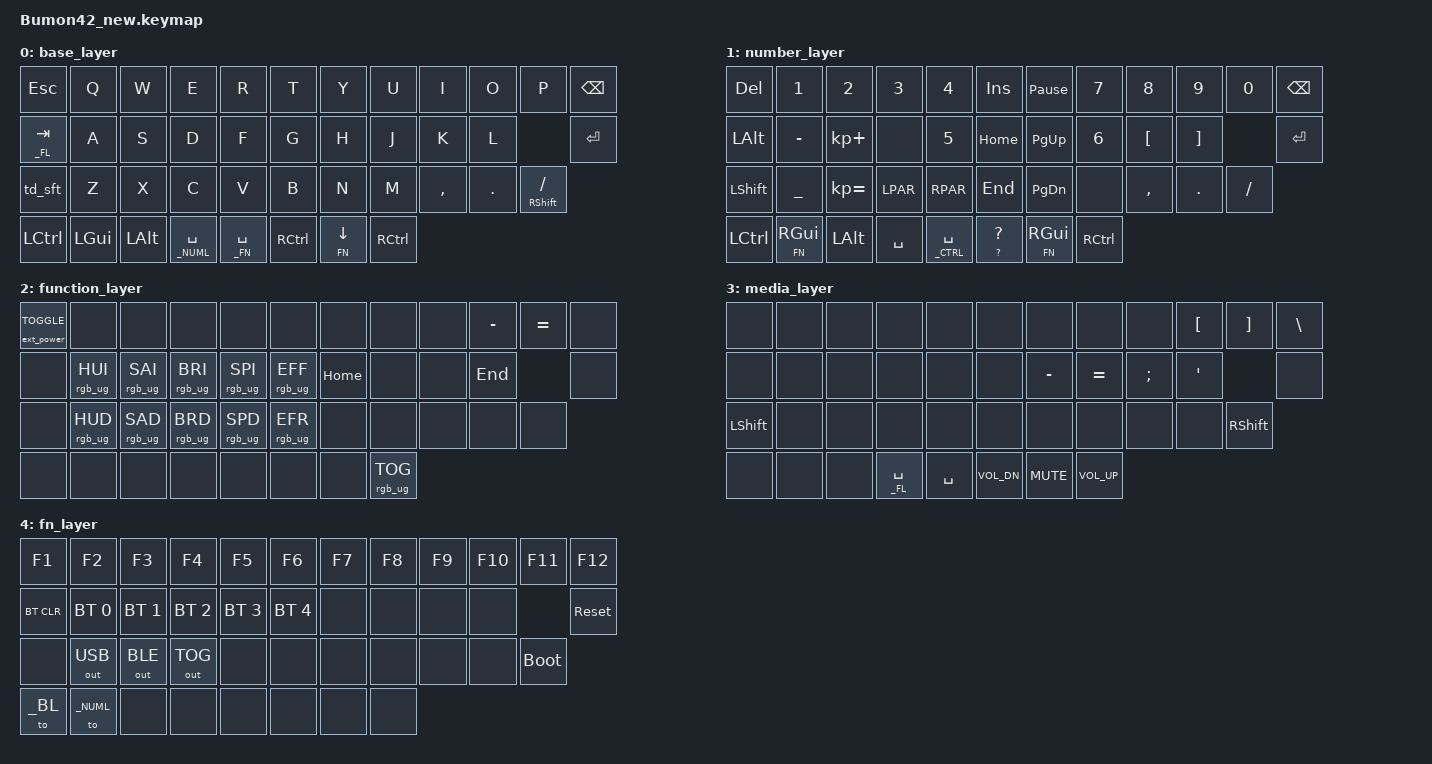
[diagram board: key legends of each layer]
#include <behaviors.dtsi>
#include <dt-bindings/zmk/bt.h>
#include <dt-bindings/zmk/ext_power.h>
#include <dt-bindings/zmk/keys.h>
#include <dt-bindings/zmk/outputs.h>
#include <dt-bindings/zmk/rgb.h>

// changed lwr and rse

#define _BL 0
#define _NUML 1
#define _FN 2
#define _CTRL 3
#define _FL 4
#define FN  5

/ {
    behaviors {
        td_sft: tap_dance_mod_tap {
            compatible = "zmk,behavior-tap-dance";
            label = "TAP_DANCE_0";
            #binding-cells = <0>;
            tapping-term-ms = <200>;
            bindings = <&kp LSHIFT>, <&kp CAPSLOCK>, <&kp TAB>;
        };
        // td_lt: tap_dance_mod_tap {
        //     compatible = "zmk,behavior-tap-dance";
        //     label = "TAP_DANCE_0";
        //     #binding-cells = <0>;
        //     tapping-term-ms = <200>;
        //     bindings = <&kp LSHIFT>, <&kp CAPSLOCK>, <&kp TAB>;
        // };
    };

    keymap {
        compatible = "zmk,keymap";

        base_layer {
            bindings = <
                &kp ESC   &kp Q    &kp W    &kp E         &kp R         &kp T     &kp Y       &kp U &kp I     &kp O   &kp P &kp BSPC
                &lt _FL TAB   &kp A    &kp S    &kp D         &kp F         &kp G     &kp H       &kp J &kp K     &kp L   &kp ENTER
                &td_sft &kp Z    &kp X    &kp C         &kp V         &kp B     &kp N       &kp M &kp COMMA &kp DOT &mt RSHIFT SLASH
                &kp LCTRL &kp LGUI &kp LALT &lt _NUML SPACE &lt _FN SPACE &kp RCTRL &lt FN DOWN &kp RCTRL
            >;

            // sensor-bindings = <&inc_dec_kp C_VOL_DN C_VOL_UP>;
        };

        number_layer {
            bindings = <
                &kp DEL   &kp N1         &kp N2       &kp N3    &kp N4        &kp INS         &kp PAUSE_BREAK &kp N7 &kp N8    &kp N9  &kp N0 &kp BSPC
                &kp LALT  &kp MINUS      &kp KP_PLUS  &none     &kp N5        &kp HOME        &kp PG_UP       &kp N6 &kp LBKT     &kp RBKT   &kp ENTER
                &kp LSHFT &kp UNDERSCORE &kp KP_EQUAL &LPAR     &RPAR         &kp END         &kp PG_DN       &none   &kp COMMA &kp DOT &kp SLASH
                &kp LCTRL &lt FN RGUI    &kp LALT     &kp SPACE &lt _CTRL SPACE &lt ??? &lt FN RGUI     &kp RCTRL
            >;

            // sensor-bindings = <&inc_dec_kp C_VOL_DN C_VOL_UP>;
        };

        function_layer {
            bindings = <
                &kp GRAVE &kp N1         &kp N2       &kp N3    &kp N4        &kp N5       &kp N6   &kp N7   &kp N8 &kp N9    &kp N0 &kp DEL
                &kp CAPS  &kp N5      &kp N6  &kp N7     &none         &kp KP_MINUS &kp LEFT &kp DOWN &kp UP &kp RIGHT &kp INS
                &kp LSHFT &kp UNDERSCORE &kp KP_EQUAL &none     &none         &kp KP_PLUS  &none    &none    &none  &kp UP   &kp RSHFT
                &none     &none          &none        &kp SPACE &lt _CTRL SPACE &kp LEFT   &kp DOWN &kp RIGHT
            >;

            // sensor-bindings = <&inc_dec_kp PG_UP PG_DN>;
        };

        media_layer {
            bindings = <
                &none     &none &none &none         &none     &none        &none      &none     &none    &kp LBKT &kp RBKT &kp BSLH
                &none     &none &none &none         &none     &none        &kp MINUS  &kp EQUAL &kp SEMI &kp SQT  &none
                &kp LSHFT &none &none &none         &none     &none        &none      &none     &none    &none    &kp RSHFT
                &none     &none &none &lt _FL SPACE &kp SPACE &kp C_VOL_DN &kp C_MUTE &kp C_VOL_UP
            >;

            // sensor-bindings = <&inc_dec_kp C_VOL_DN C_VOL_UP>;
        };

        function_layer {
            bindings =<
                &ext_power EXT_POWER_TOGGLE_CMD &none           &none           &none           &none           &none           &none    &none &none &kp MINUS &kp EQUAL &none
                &none                           &rgb_ug RGB_HUI &rgb_ug RGB_SAI &rgb_ug RGB_BRI &rgb_ug RGB_SPI &rgb_ug RGB_EFF &kp HOME &none &none &kp END   &none
                &none                           &rgb_ug RGB_HUD &rgb_ug RGB_SAD &rgb_ug RGB_BRD &rgb_ug RGB_SPD &rgb_ug RGB_EFR &none    &none &none &none     &none
                &none                           &none           &none           &none           &none           &none           &none    &rgb_ug RGB_TOG
            >;

            sensor-bindings = <&inc_dec_kp C_VOL_DN C_VOL_UP>;
        };

        fn_layer {
            bindings = <
                &kp F1     &kp F2       &kp F3       &kp F4       &kp F5       &kp F6       &kp F7 &kp F8 &kp F9 &kp F10 &kp F11 &kp F12
                &bt BT_CLR &bt BT_SEL 0 &bt BT_SEL 1 &bt BT_SEL 2 &bt BT_SEL 3 &bt BT_SEL 4 &none  &none  &none  &none   &sys_reset
                &none      &out OUT_USB &out OUT_BLE &out OUT_TOG &none        &none        &none  &none  &none  &none   &bootloader
                &to _BL    &to _NUML      &none        &none        &none        &none        &none  &none
            >;

            // sensor-bindings = <&inc_dec_kp C_VOL_DN C_VOL_UP>;
        };
    };
};
